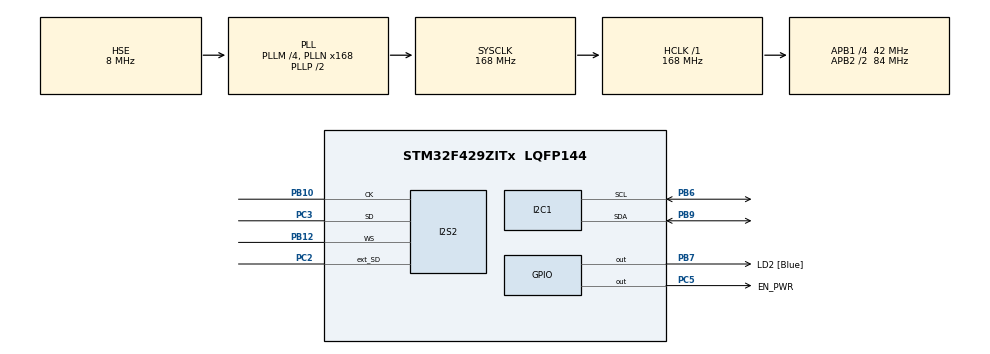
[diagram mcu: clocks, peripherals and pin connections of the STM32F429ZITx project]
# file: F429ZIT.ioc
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Dma.I2S2_EXT_TX.1.Direction=DMA_MEMORY_TO_PERIPH
Dma.I2S2_EXT_TX.1.FIFOMode=DMA_FIFOMODE_ENABLE
Dma.I2S2_EXT_TX.1.FIFOThreshold=DMA_FIFO_THRESHOLD_FULL
Dma.I2S2_EXT_TX.1.Instance=DMA1_Stream4
Dma.I2S2_EXT_TX.1.MemBurst=DMA_MBURST_SINGLE
Dma.I2S2_EXT_TX.1.MemDataAlignment=DMA_MDATAALIGN_HALFWORD
Dma.I2S2_EXT_TX.1.MemInc=DMA_MINC_ENABLE
Dma.I2S2_EXT_TX.1.Mode=DMA_NORMAL
Dma.I2S2_EXT_TX.1.PeriphBurst=DMA_PBURST_SINGLE
Dma.I2S2_EXT_TX.1.PeriphDataAlignment=DMA_PDATAALIGN_HALFWORD
Dma.I2S2_EXT_TX.1.PeriphInc=DMA_PINC_DISABLE
Dma.I2S2_EXT_TX.1.Priority=DMA_PRIORITY_HIGH
Dma.Request0=SPI2_RX
Dma.Request1=I2S2_EXT_TX
Dma.SPI2_RX.0.Direction=DMA_PERIPH_TO_MEMORY
Dma.SPI2_RX.0.FIFOMode=DMA_FIFOMODE_ENABLE
Dma.SPI2_RX.0.FIFOThreshold=DMA_FIFO_THRESHOLD_FULL
Dma.SPI2_RX.0.Instance=DMA1_Stream3
Dma.SPI2_RX.0.MemBurst=DMA_MBURST_SINGLE
Dma.SPI2_RX.0.MemDataAlignment=DMA_MDATAALIGN_HALFWORD
Dma.SPI2_RX.0.MemInc=DMA_MINC_ENABLE
Dma.SPI2_RX.0.Mode=DMA_NORMAL
Dma.SPI2_RX.0.PeriphBurst=DMA_PBURST_SINGLE
Dma.SPI2_RX.0.PeriphDataAlignment=DMA_PDATAALIGN_HALFWORD
Dma.SPI2_RX.0.PeriphInc=DMA_PINC_DISABLE
Dma.SPI2_RX.0.Priority=DMA_PRIORITY_HIGH
FREERTOS.Tasks01=defaultTask,-2,1024,StartDefaultTask,Default,NULL,Dynamic,NULL,NULL
I2S2.AudioFreq=I2S_AUDIOFREQ_48K
I2S2.DataFormat=I2S_DATAFORMAT_16B
I2S2.ErrorAudioFreq=0.0 %
I2S2.FullDuplexMode=I2S_FULLDUPLEXMODE_ENABLE
I2S2.Instance=SPI$Index
I2S2.Mode=I2S_MODE_MASTER_RX
I2S2.RealAudioFreq=48.0 KHz
I2S2.VirtualMode=I2S_MODE_MASTER
Mcu.Family=STM32F4
Mcu.Name=STM32F429ZITx
Mcu.Package=LQFP144
NVIC.DMA1_Stream3_IRQn=true\:5\:0\:false\:false\:true\:true\:false\:true\:true
NVIC.DMA1_Stream4_IRQn=true\:5\:0\:false\:false\:true\:true\:false\:true\:true
NVIC.PriorityGroup=NVIC_PRIORITYGROUP_4
NVIC.TIM4_IRQn=true\:15\:0\:false\:false\:true\:false\:false\:true\:true
NVIC.TimeBase=TIM4_IRQn
NVIC.TimeBaseIP=TIM4
PA11.GPIO_Label=USB_DM
PA11.Signal=USB_OTG_FS_DM
PA12.GPIO_Label=USB_DP
PA12.Signal=USB_OTG_FS_DP
PA13.GPIO_Label=TMS
PA13.Mode=Serial_Wire
PA13.Signal=SYS_JTMS-SWDIO
PA14.GPIO_Label=TCK
PA14.Mode=Serial_Wire
PA14.Signal=SYS_JTCK-SWCLK
PB10.Mode=Full_Duplex_Master
PB10.Signal=I2S2_CK
PB12.Mode=Full_Duplex_Master
PB12.Signal=I2S2_WS
PB6.Mode=I2C
PB6.Signal=I2C1_SCL
PB7.GPIO_Label=LD2 [Blue]
PB7.Signal=GPIO_Output
PB9.Mode=I2C
PB9.Signal=I2C1_SDA
PC14/OSC32_IN.Mode=LSE-External-Oscillator
PC14/OSC32_IN.Signal=RCC_OSC32_IN
PC15/OSC32_OUT.Mode=LSE-External-Oscillator
PC15/OSC32_OUT.Signal=RCC_OSC32_OUT
PC2.Mode=Full_Duplex_Master
PC2.Signal=I2S2_ext_SD
PC3.Mode=Full_Duplex_Master
PC3.Signal=I2S2_SD
PC5.GPIO_Label=EN_PWR
PC5.GPIO_PuPd=GPIO_PULLDOWN
PC5.Signal=GPIO_Output
PD8.GPIO_Label=STLK_RX [STM32F103CBT6_PA3]
PD8.Signal=USART3_TX
PD9.GPIO_Label=STLK_TX [STM32F103CBT6_PA2]
PD9.Signal=USART3_RX
PH0/OSC_IN.GPIO_Label=MCO [STM32F103CBT6_PA8]
PH0/OSC_IN.Mode=HSE-External-Clock-Source
PH0/OSC_IN.Signal=RCC_OSC_IN
PH1/OSC_OUT.Mode=HSE-External-Clock-Source
PH1/OSC_OUT.Signal=RCC_OSC_OUT
ProjectManager.HeapSize=0x800
ProjectManager.StackSize=0x800
ProjectManager.TargetToolchain=EWARM V8.50
RCC.48MHZClocksFreq_Value=48000000
RCC.AHBFreq_Value=168000000
RCC.APB1CLKDivider=RCC_HCLK_DIV4
RCC.APB1Freq_Value=42000000
RCC.APB1TimFreq_Value=84000000
RCC.APB2CLKDivider=RCC_HCLK_DIV2
RCC.APB2Freq_Value=84000000
RCC.APB2TimCLKDivider=2
RCC.APB2TimFreq_Value=168000000
RCC.CortexFreq_Value=168000000
RCC.HCLKFreq_Value=168000000
RCC.HSE_VALUE=8000000
RCC.HSI_VALUE=16000000
RCC.PLLM=4
RCC.PLLMUL=RCC_PLL_MUL9
RCC.PLLN=168
RCC.PLLQ=7
RCC.PLLSourceVirtual=RCC_PLLSOURCE_HSE
RCC.PRESCALERUSB=RCC_USBCLKSOURCE_PLL_DIV1_5
RCC.SYSCLKFreq_VALUE=168000000
RCC.SYSCLKSource=RCC_SYSCLKSOURCE_PLLCLK
RCC.SYSCLKSourceVirtual=RCC_SYSCLKSOURCE_PLLCLK
RCC.USBFreq_Value=48000000
RCC.VCOOutputFreq_Value=336000000
VP_FREERTOS_VS_CMSIS_V1.Mode=CMSIS_V1
VP_SYS_VS_tim4.Mode=TIM4
board=NUCLEO-F429ZI

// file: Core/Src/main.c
/* USER CODE BEGIN Header */
/**
  ******************************************************************************
  * @file           : main.c
  * @brief          : Main program body
  ******************************************************************************
  * @attention
  *
  * Copyright (c) 2025 STMicroelectronics.
  * All rights reserved.
  *
  * This software is licensed under terms that can be found in the LICENSE file
  * in the root directory of this software component.
  * If no LICENSE file comes with this software, it is provided AS-IS.
  *
  ******************************************************************************
  */
/* USER CODE END Header */
#include "main.h"
#include "cmsis_os.h"
#include "dma.h"
#include "i2c.h"
#include "i2s.h"
#include "gpio.h"

void SystemClock_Config(void);
void MX_FREERTOS_Init(void);

int main(void)
{

  /* MCU Configuration--------------------------------------------------------*/

  /* Reset of all peripherals, Initializes the Flash interface and the Systick. */
  HAL_Init();

  /* Configure the system clock */
  SystemClock_Config();

  /* Initialize all configured peripherals */
  MX_GPIO_Init();
  MX_DMA_Init();
  MX_I2S2_Init();
  MX_I2C1_Init();

  /* Call init function for freertos objects (in cmsis_os2.c) */
  MX_FREERTOS_Init();

  /* Start scheduler */
  osKernelStart();

  /* We should never get here as control is now taken by the scheduler */

  /* Infinite loop */
  while (1)
  {

  }
}

void SystemClock_Config(void)
{
  RCC_OscInitTypeDef RCC_OscInitStruct = {0};
  RCC_ClkInitTypeDef RCC_ClkInitStruct = {0};

  /** Configure the main internal regulator output voltage
  */
  __HAL_RCC_PWR_CLK_ENABLE();
  __HAL_PWR_VOLTAGESCALING_CONFIG(PWR_REGULATOR_VOLTAGE_SCALE1);

  /** Initializes the RCC Oscillators according to the specified parameters
  * in the RCC_OscInitTypeDef structure.
  */
  RCC_OscInitStruct.OscillatorType = RCC_OSCILLATORTYPE_HSE;
  RCC_OscInitStruct.HSEState = RCC_HSE_BYPASS;
  RCC_OscInitStruct.PLL.PLLState = RCC_PLL_ON;
  RCC_OscInitStruct.PLL.PLLSource = RCC_PLLSOURCE_HSE;
  RCC_OscInitStruct.PLL.PLLM = 4;
  RCC_OscInitStruct.PLL.PLLN = 168;
  RCC_OscInitStruct.PLL.PLLP = RCC_PLLP_DIV2;
  RCC_OscInitStruct.PLL.PLLQ = 7;
  if (HAL_RCC_OscConfig(&RCC_OscInitStruct) != HAL_OK)
  {
    Error_Handler();
  }

  /** Initializes the CPU, AHB and APB buses clocks
  */
  RCC_ClkInitStruct.ClockType = RCC_CLOCKTYPE_HCLK|RCC_CLOCKTYPE_SYSCLK
                              |RCC_CLOCKTYPE_PCLK1|RCC_CLOCKTYPE_PCLK2;
  RCC_ClkInitStruct.SYSCLKSource = RCC_SYSCLKSOURCE_PLLCLK;
  RCC_ClkInitStruct.AHBCLKDivider = RCC_SYSCLK_DIV1;
  RCC_ClkInitStruct.APB1CLKDivider = RCC_HCLK_DIV4;
  RCC_ClkInitStruct.APB2CLKDivider = RCC_HCLK_DIV2;

  if (HAL_RCC_ClockConfig(&RCC_ClkInitStruct, FLASH_LATENCY_5) != HAL_OK)
  {
    Error_Handler();
  }
}

void HAL_TIM_PeriodElapsedCallback(TIM_HandleTypeDef *htim)
{
  if (htim->Instance == TIM4) {
    HAL_IncTick();
  }
}

void Error_Handler(void)
{
  __disable_irq();
  while (1)
  {
  }
}

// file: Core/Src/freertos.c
/* USER CODE BEGIN Header */
/**
  ******************************************************************************
  * File Name          : freertos.c
  * Description        : Code for freertos applications
  ******************************************************************************
  * @attention
  *
  * Copyright (c) 2025 STMicroelectronics.
  * All rights reserved.
  *
  * This software is licensed under terms that can be found in the LICENSE file
  * in the root directory of this software component.
  * If no LICENSE file comes with this software, it is provided AS-IS.
  *
  ******************************************************************************
  */
/* USER CODE END Header */

#include "FreeRTOS.h"
#include "task.h"
#include "main.h"
#include "cmsis_os.h"

/* USER CODE BEGIN Includes */
#include "dma.h"
#include "i2c.h"
#include "i2s.h"
#include "wm8960.h"
#include <stdio.h>
/* USER CODE END Includes */

osThreadId defaultTaskHandle;

/* USER CODE BEGIN FunctionPrototypes */
void test_audio_tx();
void test_audio_rx();
void test_audio_tx_rx();
/* USER CODE END FunctionPrototypes */

void StartDefaultTask(void const * argument);

void MX_FREERTOS_Init(void); /* (MISRA C 2004 rule 8.1) */

/* GetIdleTaskMemory prototype (linked to static allocation support) */
void vApplicationGetIdleTaskMemory( StaticTask_t **ppxIdleTaskTCBBuffer, StackType_t **ppxIdleTaskStackBuffer, uint32_t *pulIdleTaskStackSize );

/* USER CODE BEGIN GET_IDLE_TASK_MEMORY */
static StaticTask_t xIdleTaskTCBBuffer;
static StackType_t xIdleStack[configMINIMAL_STACK_SIZE];

void vApplicationGetIdleTaskMemory( StaticTask_t **ppxIdleTaskTCBBuffer, StackType_t **ppxIdleTaskStackBuffer, uint32_t *pulIdleTaskStackSize )
{
  *ppxIdleTaskTCBBuffer = &xIdleTaskTCBBuffer;
  *ppxIdleTaskStackBuffer = &xIdleStack[0];
  *pulIdleTaskStackSize = configMINIMAL_STACK_SIZE;
  /* place for user code */
}
/* USER CODE END GET_IDLE_TASK_MEMORY */

void MX_FREERTOS_Init(void) {

  /* Create the thread(s) */
  /* definition and creation of defaultTask */
  osThreadDef(defaultTask, StartDefaultTask, osPriorityLow, 0, 1024);
  defaultTaskHandle = osThreadCreate(osThread(defaultTask), NULL);

}

void StartDefaultTask(void const * argument)
{
  /* USER CODE BEGIN StartDefaultTask */
    init_wm8960(WM8960_INPUT_LINEIN);
    // set_wm8960_input_src(WM8960_INPUT_LINEIN);
    // set_wm8960_input_src(WM8960_INPUT_MIC);

    test_audio_rx();

  /* Infinite loop */
    for(;;)
    {
        osDelay(1);
    }
  /* USER CODE END StartDefaultTask */
}
